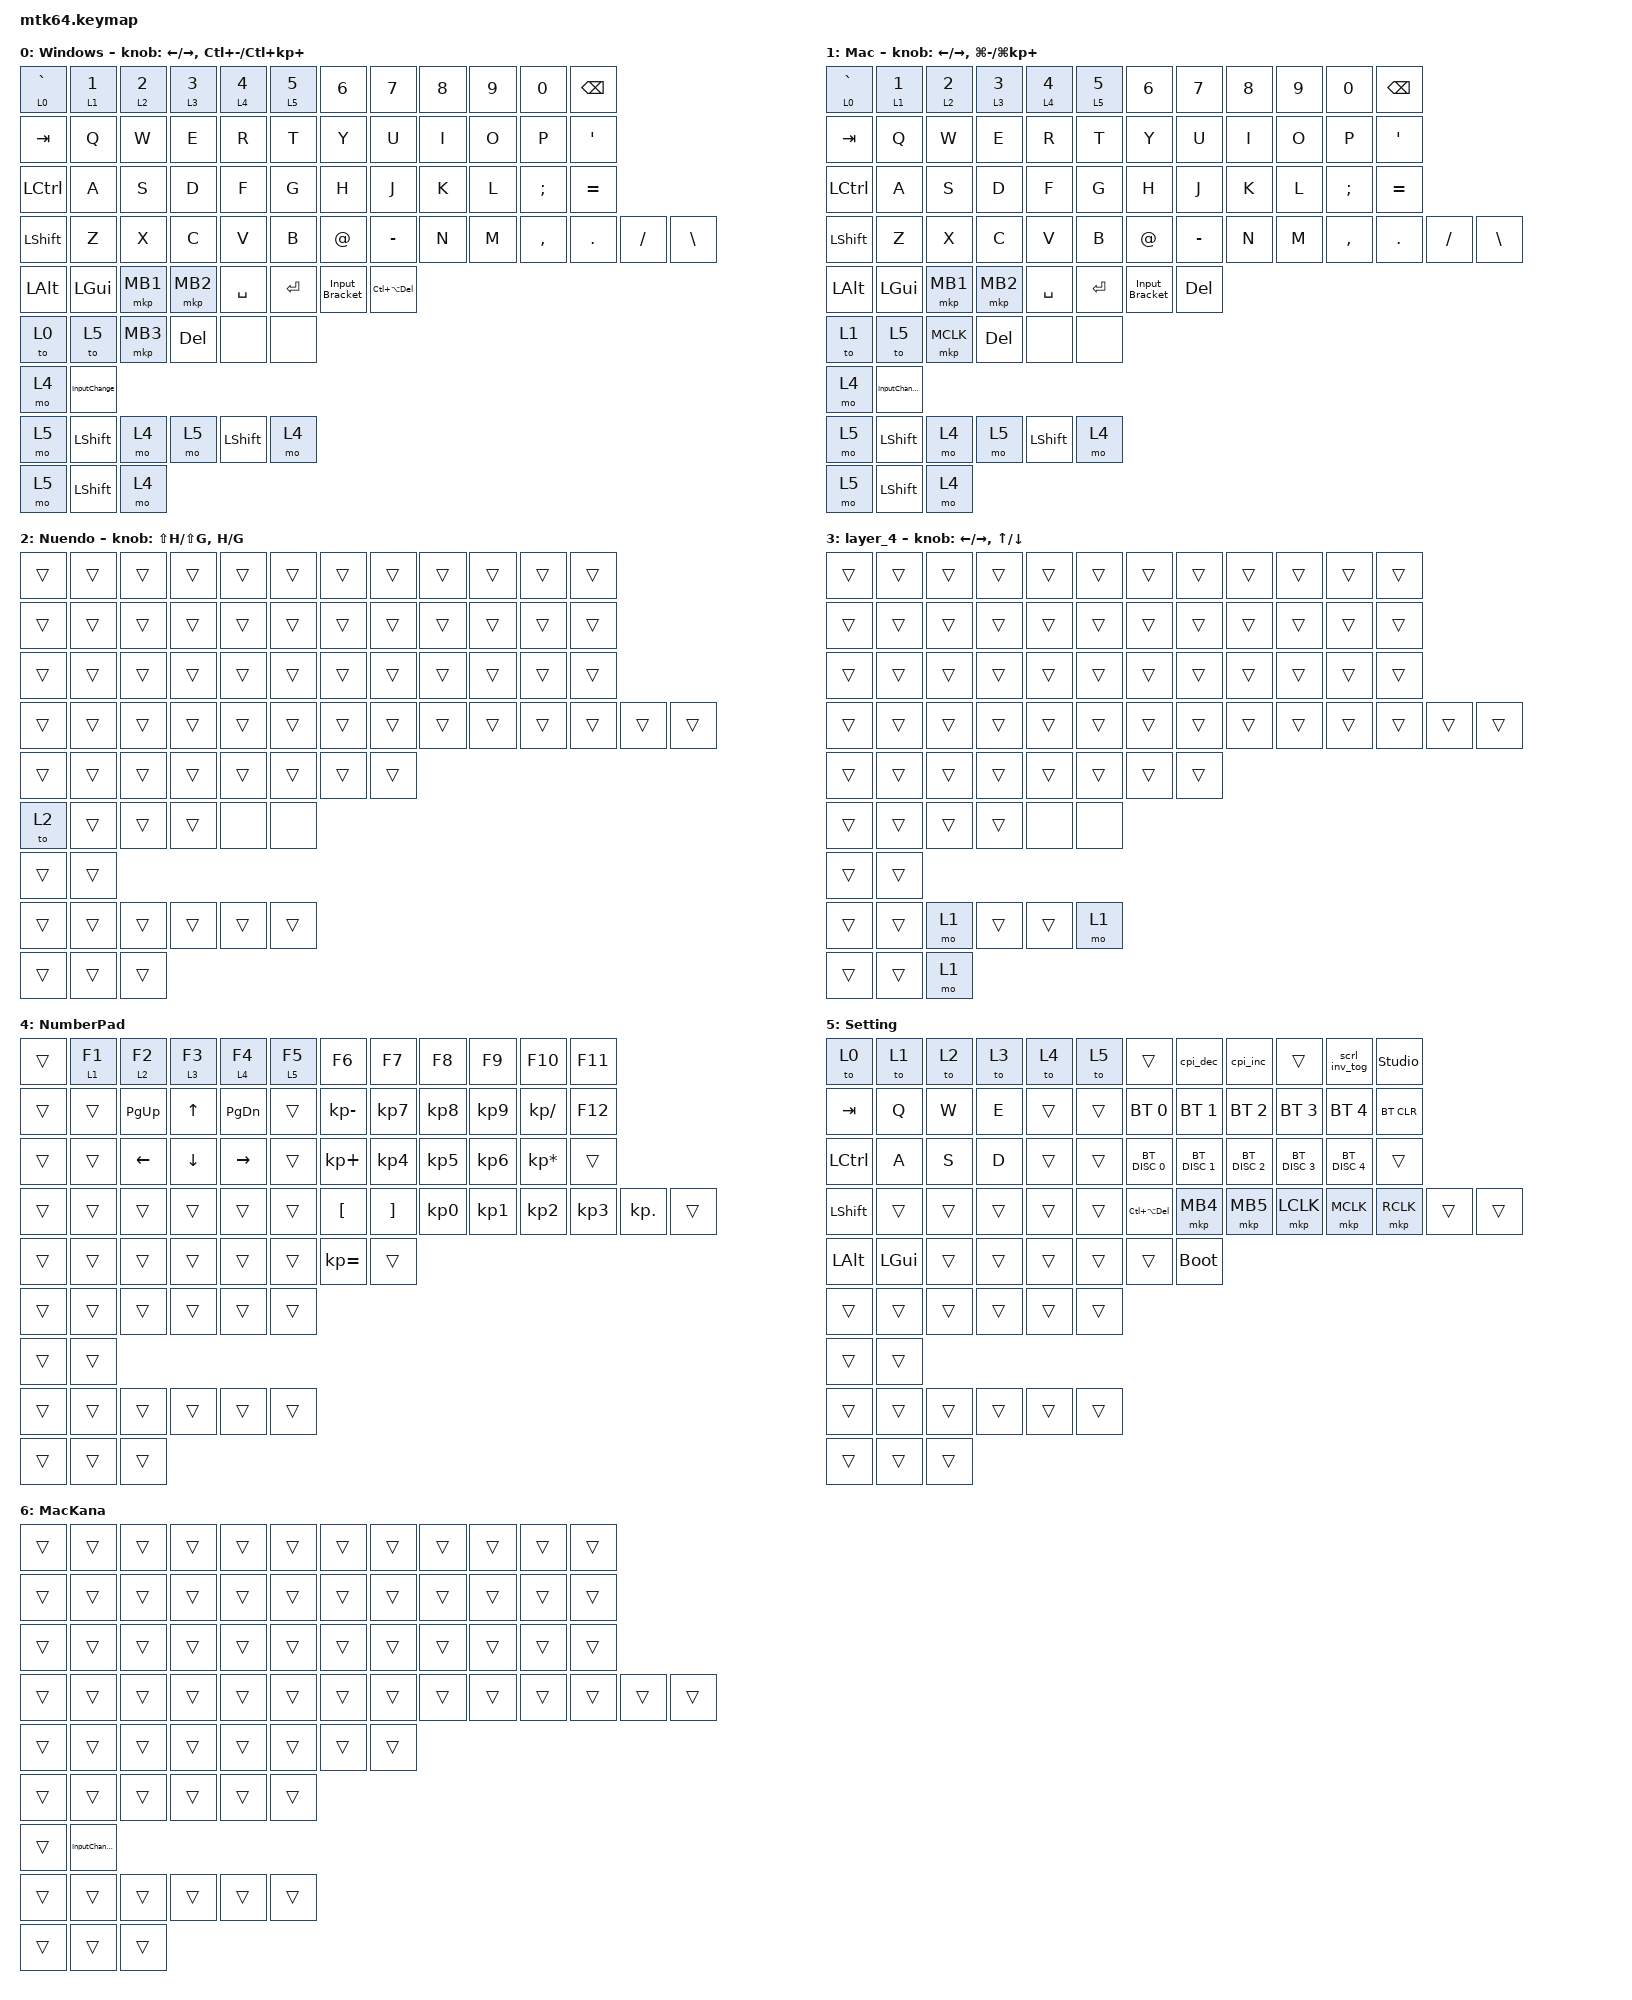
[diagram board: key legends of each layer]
// スクロール量の設定: pointing.h より前に定義する (ZMK main では ZMK_POINTING_* に改名)
#define ZMK_POINTING_DEFAULT_SCRL_VAL 100

#include "keycode_japanese.h"
#include <behaviors.dtsi>
#include <dt-bindings/zmk/bt.h>
#include <dt-bindings/zmk/keys.h>
#include <dt-bindings/zmk/pointing.h>
#include <input/processors.dtsi>

&mt {
    flavor = "balanced";
    quick-tap-ms = <0>;
    tapping-term-ms = <800>;
};

/ {
    macros {
        Length1: Length1 {
            compatible = "zmk,behavior-macro";
            #binding-cells = <0>;
            bindings = <&kp LC(LA(LG(NUMBER_1)))>;
            label = "LENGTH1";
        };

        Length2: Length2 {
            compatible = "zmk,behavior-macro";
            #binding-cells = <0>;
            bindings = <&kp LC(LA(LG(NUMBER_2)))>;
            label = "LENGTH2";
        };

        Length4: Length4 {
            compatible = "zmk,behavior-macro";
            #binding-cells = <0>;
            bindings = <&kp LC(LA(LG(NUMBER_4)))>;
            label = "LENGTH4";
        };

        Length8: Length8 {
            compatible = "zmk,behavior-macro";
            #binding-cells = <0>;
            bindings = <&kp LC(LA(LG(N8)))>;
            label = "LENGTH8";
        };

        Length16: Length16 {
            compatible = "zmk,behavior-macro";
            #binding-cells = <0>;
            bindings = <&kp LC(LA(LG(NUMBER_6)))>;
            label = "LENGTH16";
        };

        Length32: Length32 {
            compatible = "zmk,behavior-macro";
            #binding-cells = <0>;
            bindings = <&kp LC(LA(LG(NUMBER_3)))>;
            label = "LENGTH32";
        };

        TripletOn: TripletOn {
            compatible = "zmk,behavior-macro";
            #binding-cells = <0>;
            bindings = <&kp LC(LA(LG(F3)))>;
            label = "TRIPLETON";
        };

        CtrlAltDelete: CtrlAltDelete {
            compatible = "zmk,behavior-macro";
            #binding-cells = <0>;
            bindings = <&kp LC(LA(DELETE))>;
            label = "CTRLALTDELETE";
        };

        InputChange: InputChange {
            compatible = "zmk,behavior-macro";
            #binding-cells = <0>;
            bindings = <&kp LG(SPACE)>;
            label = "INPUTCHANGE";
        };

        InputChangeMac: InputChangeMac {
            compatible = "zmk,behavior-macro";
            #binding-cells = <0>;
            // 押すたびに かな(LANG1) / 英数(LANG2) を交互に送る。
            // かな送信と同時にレイヤー6(MacKana)を ON にし、次の押下で英数を送って OFF に戻す
            bindings = <&kp LANG1 &tog 6>;
            label = "INPUTCHANGEMAC";
        };

        InputChangeMacEisu: InputChangeMacEisu {
            compatible = "zmk,behavior-macro";
            #binding-cells = <0>;
            bindings = <&kp LANG2 &tog 6>;
            label = "INPUTCHANGEMACEISU";
        };

        Input_Bracket: Input_Bracket {
            compatible = "zmk,behavior-macro";
            #binding-cells = <0>;
            bindings = <&kp LEFT_BRACKET &kp RIGHT_BRACKET &kp LEFT_ARROW>;
            label = "INPUT_BRACKET";
        };
    };

    behaviors {
        // タップでキー入力、長押しでレイヤー移動:  &to_kp <レイヤー番号> <キー>
        to_kp: to_kp {
            compatible = "zmk,behavior-hold-tap";
            label = "TO_KP";
            bindings = <&to>, <&kp>;

            #binding-cells = <2>;
            tapping-term-ms = <750>;
        };

        inc_dec_msc: inc_dec_msc {
            compatible = "zmk,behavior-sensor-rotate-var";
            label = "INC_DEC_MSC";
            #sensor-binding-cells = <2>;
            bindings = <&msc>, <&msc>;
        };

        mkp_kp: mkp_kp {
            compatible = "zmk,behavior-hold-tap";
            label = "MKP_KP";
            bindings = <&kp>, <&mkp>;

            #binding-cells = <2>;
            tapping-term-ms = <200>;
        };

        Length1kp: Length1kp {
            compatible = "zmk,behavior-hold-tap";
            label = "LENGTH1KP";
            bindings = <&Length1>, <&kp>;

            #binding-cells = <2>;
            tapping-term-ms = <200>;
        };

        Length2kp: Length2kp {
            compatible = "zmk,behavior-hold-tap";
            label = "LENGTH2KP";
            bindings = <&Length2>, <&kp>;

            #binding-cells = <2>;
            tapping-term-ms = <200>;
        };

        Length4kp: Length4kp {
            compatible = "zmk,behavior-hold-tap";
            label = "LENGTH4KP";
            bindings = <&Length4>, <&kp>;

            #binding-cells = <2>;
            tapping-term-ms = <200>;
        };

        Length8kp: Length8kp {
            compatible = "zmk,behavior-hold-tap";
            label = "LENGTH8KP";
            bindings = <&Length8>, <&kp>;

            #binding-cells = <2>;
            tapping-term-ms = <200>;
        };

        Length16kp: Length16kp {
            compatible = "zmk,behavior-hold-tap";
            label = "LENGTH16KP";
            bindings = <&Length16>, <&kp>;

            #binding-cells = <2>;
            tapping-term-ms = <200>;
        };

        Length32kp: Length32kp {
            compatible = "zmk,behavior-hold-tap";
            label = "LENGTH32KP";
            bindings = <&Length32>, <&kp>;

            #binding-cells = <2>;
            tapping-term-ms = <200>;
        };

        Triplet_kp: Triplet_kp {
            compatible = "zmk,behavior-hold-tap";
            label = "TRIPLET_KP";
            bindings = <&Length32>, <&kp>;

            #binding-cells = <2>;
            tapping-term-ms = <200>;
        };
    };

    combos {
        compatible = "zmk,combos";

        CAD {
            bindings = <&CtrlAltDelete>;
            key-positions = <25 39 27>;
        };
    };

    keymap {
        compatible = "zmk,keymap";

        Windows {
            bindings = <
                &to_kp 0 GRAVE  &to_kp 1 NUMBER_1  &to_kp 2 NUMBER_2  &to_kp 3 NUMBER_3  &to_kp 4 NUMBER_4  &to_kp 5 NUMBER_5  &kp NUMBER_6    &kp N7              &kp N8  &kp N9  &kp N0         &kp BACKSPACE
                &kp TAB         &kp Q              &kp W              &kp E              &kp R              &kp T              &kp Y           &kp U               &kp I   &kp O   &kp P          &kp SQT
                &kp LCTRL       &kp A              &kp S              &kp D              &kp F              &kp G              &kp H           &kp J               &kp K   &kp L   &kp SEMICOLON  &kp EQUAL
                &kp LSHFT       &kp Z              &kp X              &kp C              &kp V              &kp B              &kp AT_SIGN     &kp MINUS           &kp N   &kp M   &kp COMMA      &kp DOT        &kp SLASH  &kp BACKSLASH
                &kp LALT        &kp LGUI           &mkp MB1           &mkp MB2           &kp SPACE          &kp ENTER          &Input_Bracket  &kp LC(LA(DELETE))
                &to 0           &to 5              &mkp MB3           &kp DELETE         &none              &none
                &mo 4           &InputChange
                &mo 5           &kp LEFT_SHIFT     &mo 4              &mo 5              &kp LEFT_SHIFT     &mo 4
                &mo 5           &kp LEFT_SHIFT     &mo 4
            >;

            sensor-bindings =
                <&inc_dec_kp LEFT_ARROW RIGHT_ARROW>,
                <&inc_dec_kp LC(MINUS) LC(KP_PLUS)>;
        };

        Mac {
            bindings = <
                &to_kp 0 GRAVE  &to_kp 1 NUMBER_1  &to_kp 2 NUMBER_2  &to_kp 3 NUMBER_3  &to_kp 4 NUMBER_4  &to_kp 5 NUMBER_5  &kp NUMBER_6    &kp N7      &kp N8  &kp N9  &kp N0         &kp BACKSPACE
                &kp TAB         &kp Q              &kp W              &kp E              &kp R              &kp T              &kp Y           &kp U       &kp I   &kp O   &kp P          &kp SQT
                &kp LCTRL       &kp A              &kp S              &kp D              &kp F              &kp G              &kp H           &kp J       &kp K   &kp L   &kp SEMICOLON  &kp EQUAL
                &kp LSHFT       &kp Z              &kp X              &kp C              &kp V              &kp B              &kp AT_SIGN     &kp MINUS   &kp N   &kp M   &kp COMMA      &kp DOT        &kp SLASH  &kp BACKSLASH
                &kp LALT        &kp LGUI           &mkp MB1           &mkp MB2           &kp SPACE          &kp ENTER          &Input_Bracket  &kp DELETE
                &to 1           &to 5              &mkp MCLK          &kp DELETE         &none              &none
                &mo 4           &InputChangeMac
                &mo 5           &kp LEFT_SHIFT     &mo 4              &mo 5              &kp LEFT_SHIFT     &mo 4
                &mo 5           &kp LEFT_SHIFT     &mo 4
            >;

            sensor-bindings =
                <&inc_dec_kp LEFT_ARROW RIGHT_ARROW>,
                <&inc_dec_kp LG(MINUS) LG(KP_PLUS)>;
        };

        Nuendo {
            bindings = <
                &trans  &trans  &trans  &trans  &trans  &trans  &trans  &trans  &trans  &trans  &trans  &trans
                &trans  &trans  &trans  &trans  &trans  &trans  &trans  &trans  &trans  &trans  &trans  &trans
                &trans  &trans  &trans  &trans  &trans  &trans  &trans  &trans  &trans  &trans  &trans  &trans
                &trans  &trans  &trans  &trans  &trans  &trans  &trans  &trans  &trans  &trans  &trans  &trans  &trans  &trans
                &trans  &trans  &trans  &trans  &trans  &trans  &trans  &trans
                &to 2   &trans  &trans  &trans  &none   &none
                &trans  &trans
                &trans  &trans  &trans  &trans  &trans  &trans
                &trans  &trans  &trans
            >;

            sensor-bindings = <&inc_dec_kp LS(H) LS(G)>, <&inc_dec_kp H G>;
        };

        layer_4 {
            bindings = <
&trans  &trans  &trans  &trans  &trans  &trans  &trans  &trans  &trans  &trans  &trans  &trans  &trans  &trans  &trans  &trans  &trans  &trans  &trans  &trans  &trans  &trans  &trans  &trans  &trans  &trans  &trans  &trans  &trans  &trans  &trans  &trans  &trans  &trans  &trans  &trans  &trans  &trans  &trans  &trans  &trans  &trans  &trans  &trans  &trans  &trans  &trans  &trans  &trans  &trans  &trans  &trans  &trans  &trans  &trans  &trans  &trans  &trans  &trans  &trans  &trans  &trans  &none  &none  &trans  &trans  &trans  &trans  &mo 1  &trans  &trans  &mo 1  &trans  &trans  &mo 1
            >;

            sensor-bindings = <
                &inc_dec_kp LEFT_ARROW RIGHT_ARROW
                &inc_dec_kp UP_ARROW   DOWN_ARROW
            >;
        };

        NumberPad {
            bindings = <
                &trans  &to_kp 1 F1  &to_kp 2 F2     &to_kp 3 F3   &to_kp 4 F4    &to_kp 5 F5  &kp F6            &kp F7             &kp F8           &kp F9           &kp F10          &kp F11
                &trans  &trans       &kp PAGE_UP     &kp UP_ARROW  &kp PAGE_DOWN  &trans       &kp KP_MINUS      &kp KP_NUMBER_7    &kp KP_NUMBER_8  &kp KP_NUMBER_9  &kp KP_DIVIDE    &kp F12
                &trans  &trans       &kp LEFT_ARROW  &kp DOWN      &kp RIGHT      &trans       &kp KP_PLUS       &kp KP_NUMBER_4    &kp KP_NUMBER_5  &kp KP_NUMBER_6  &kp KP_ASTERISK  &trans
                &trans  &trans       &trans          &trans        &trans         &trans       &kp LEFT_BRACKET  &kp RIGHT_BRACKET  &kp KP_NUMBER_0  &kp KP_NUMBER_1  &kp KP_NUMBER_2  &kp KP_NUMBER_3  &kp KP_DOT  &trans
                &trans  &trans       &trans          &trans        &trans         &trans       &kp KP_EQUAL      &trans
                &trans  &trans       &trans          &trans        &trans         &trans
                &trans  &trans
                &trans  &trans       &trans          &trans        &trans         &trans
                &trans  &trans       &trans
            >;
        };

        Setting {
            bindings = <
                &to 0             &to 1         &to 2   &to 3   &to 4   &to 5   &trans           &cpi_dec       &cpi_inc       &trans         &scrl_inv_tog  &studio_unlock
                &kp TAB           &kp Q         &kp W   &kp E   &trans  &trans  &bt BT_SEL 0     &bt BT_SEL 1   &bt BT_SEL 2   &bt BT_SEL 3   &bt BT_SEL 4   &bt BT_CLR
                &kp LEFT_CONTROL  &kp A         &kp S   &kp D   &trans  &trans  &bt BT_DISC 0    &bt BT_DISC 1  &bt BT_DISC 2  &bt BT_DISC 3  &bt BT_DISC 4  &trans
                &kp LEFT_SHIFT    &trans        &trans  &trans  &trans  &trans  &kp LC(LA(DEL))  &mkp MB4       &mkp MB5       &mkp LCLK      &mkp MCLK      &mkp RCLK       &trans  &trans
                &kp LEFT_ALT      &kp LEFT_GUI  &trans  &trans  &trans  &trans  &trans           &bootloader
                &trans            &trans        &trans  &trans  &trans  &trans
                &trans            &trans
                &trans            &trans        &trans  &trans  &trans  &trans
                &trans            &trans        &trans
            >;
        };

        // Mac の言語切替キーの状態保持用 (かな入力中だけ ON。同じ位置で英数を送って OFF)
        MacKana {
            display-name = "MacKana";
            bindings = <
                &trans  &trans  &trans  &trans  &trans  &trans  &trans  &trans  &trans  &trans  &trans  &trans
                &trans  &trans  &trans  &trans  &trans  &trans  &trans  &trans  &trans  &trans  &trans  &trans
                &trans  &trans  &trans  &trans  &trans  &trans  &trans  &trans  &trans  &trans  &trans  &trans
                &trans  &trans  &trans  &trans  &trans  &trans  &trans  &trans  &trans  &trans  &trans  &trans  &trans  &trans
                &trans  &trans  &trans  &trans  &trans  &trans  &trans  &trans
                &trans  &trans  &trans  &trans  &trans  &trans
                &trans  &InputChangeMacEisu
                &trans  &trans  &trans  &trans  &trans  &trans
                &trans  &trans  &trans
            >;
        };
    };
};
